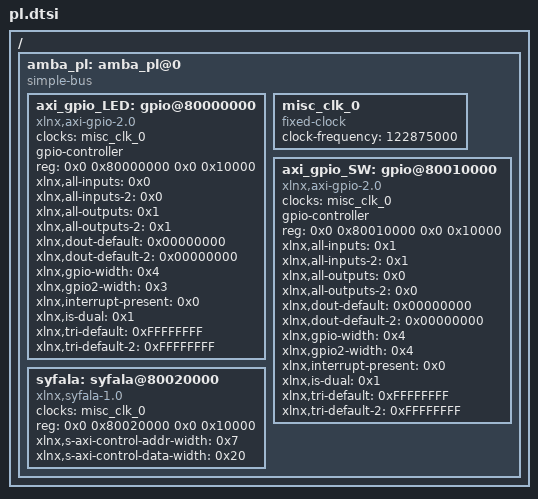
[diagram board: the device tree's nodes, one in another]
/*
 * CAUTION: This file is automatically generated by Xilinx.
 * Version: XSCT 2022.2
 * Today is: Wed Feb 28 11:40:46 2024
 */


/ {
	amba_pl: amba_pl@0 {
		#address-cells = <2>;
		#size-cells = <2>;
		compatible = "simple-bus";
		ranges ;
		axi_gpio_LED: gpio@80000000 {
			#gpio-cells = <2>;
			clock-names = "s_axi_aclk";
			clocks = <&misc_clk_0>;
			compatible = "xlnx,axi-gpio-2.0", "xlnx,xps-gpio-1.00.a";
			gpio-controller ;
			reg = <0x0 0x80000000 0x0 0x10000>;
			xlnx,all-inputs = <0x0>;
			xlnx,all-inputs-2 = <0x0>;
			xlnx,all-outputs = <0x1>;
			xlnx,all-outputs-2 = <0x1>;
			xlnx,dout-default = <0x00000000>;
			xlnx,dout-default-2 = <0x00000000>;
			xlnx,gpio-width = <0x4>;
			xlnx,gpio2-width = <0x3>;
			xlnx,interrupt-present = <0x0>;
			xlnx,is-dual = <0x1>;
			xlnx,tri-default = <0xFFFFFFFF>;
			xlnx,tri-default-2 = <0xFFFFFFFF>;
		};
		misc_clk_0: misc_clk_0 {
			#clock-cells = <0>;
			clock-frequency = <122875000>;
			compatible = "fixed-clock";
		};
		axi_gpio_SW: gpio@80010000 {
			#gpio-cells = <2>;
			clock-names = "s_axi_aclk";
			clocks = <&misc_clk_0>;
			compatible = "xlnx,axi-gpio-2.0", "xlnx,xps-gpio-1.00.a";
			gpio-controller ;
			reg = <0x0 0x80010000 0x0 0x10000>;
			xlnx,all-inputs = <0x1>;
			xlnx,all-inputs-2 = <0x1>;
			xlnx,all-outputs = <0x0>;
			xlnx,all-outputs-2 = <0x0>;
			xlnx,dout-default = <0x00000000>;
			xlnx,dout-default-2 = <0x00000000>;
			xlnx,gpio-width = <0x4>;
			xlnx,gpio2-width = <0x4>;
			xlnx,interrupt-present = <0x0>;
			xlnx,is-dual = <0x1>;
			xlnx,tri-default = <0xFFFFFFFF>;
			xlnx,tri-default-2 = <0xFFFFFFFF>;
		};
		syfala: syfala@80020000 {
			/* This is a place holder node for a custom IP, user may need to update the entries */
			clock-names = "ap_clk";
			clocks = <&misc_clk_0>;
			compatible = "xlnx,syfala-1.0";
			reg = <0x0 0x80020000 0x0 0x10000>;
			xlnx,s-axi-control-addr-width = <0x7>;
			xlnx,s-axi-control-data-width = <0x20>;
		};
	};
};
